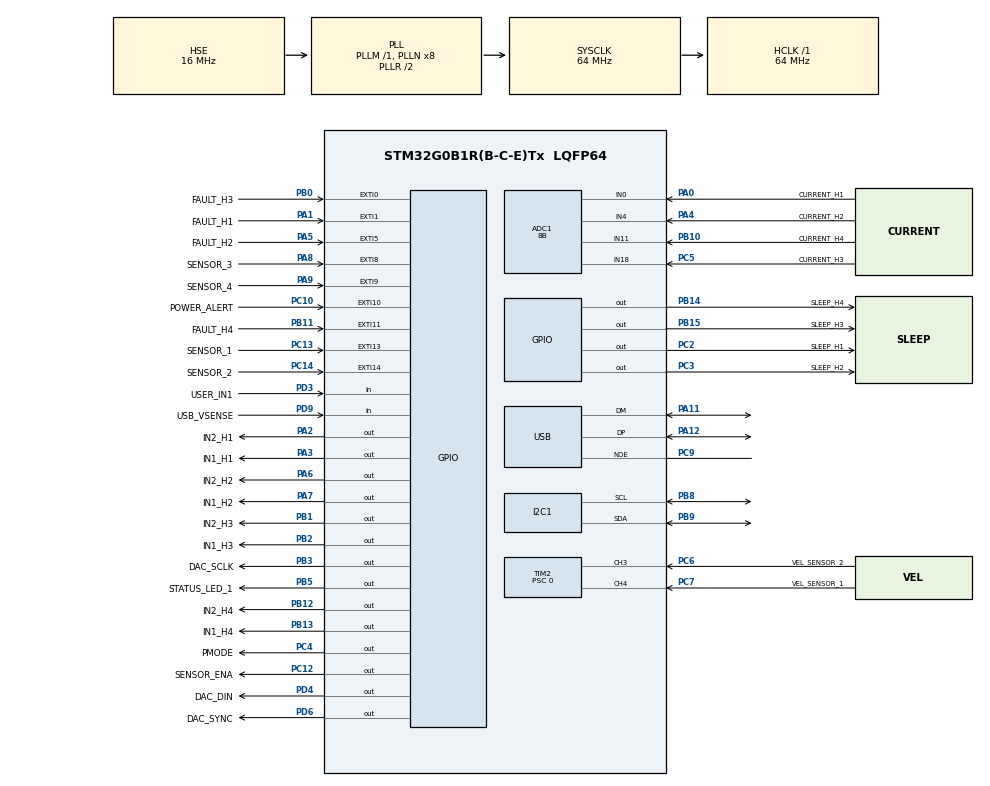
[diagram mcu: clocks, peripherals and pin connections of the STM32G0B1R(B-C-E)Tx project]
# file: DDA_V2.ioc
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ADC1.ContinuousConvMode=DISABLE
ADC1.DMAContinuousRequests=ENABLE
ADC1.EOCSelection=ADC_EOC_SEQ_CONV
ADC1.ExternalTrigConv=ADC_EXTERNALTRIG_T15_TRGO
ADC1.NbrOfConversion=1
ADC1.NbrOfConversionFlag=0
ADC1.Resolution=ADC_RESOLUTION_8B
ADC1.SamplingTimeCommon1=ADC_SAMPLETIME_79CYCLES_5
ADC1.SelectedChannel=ADC_CHANNEL_0|ADC_CHANNEL_4|ADC_CHANNEL_11|ADC_CHANNEL_18
ADC1.Sequencer=NOT_FULLY_CONFIGURABLE
ADC1.master=1
Dma.ADC1.0.Direction=DMA_PERIPH_TO_MEMORY
Dma.ADC1.0.EventEnable=DISABLE
Dma.ADC1.0.Instance=DMA1_Channel2
Dma.ADC1.0.MemDataAlignment=DMA_MDATAALIGN_BYTE
Dma.ADC1.0.MemInc=DMA_MINC_ENABLE
Dma.ADC1.0.Mode=DMA_NORMAL
Dma.ADC1.0.PeriphDataAlignment=DMA_PDATAALIGN_BYTE
Dma.ADC1.0.PeriphInc=DMA_PINC_DISABLE
Dma.ADC1.0.Polarity=HAL_DMAMUX_REQ_GEN_RISING
Dma.ADC1.0.Priority=DMA_PRIORITY_MEDIUM
Dma.ADC1.0.RequestNumber=1
Dma.ADC1.0.SignalID=NONE
Dma.ADC1.0.SyncEnable=DISABLE
Dma.ADC1.0.SyncPolarity=HAL_DMAMUX_SYNC_NO_EVENT
Dma.ADC1.0.SyncRequestNumber=1
Dma.ADC1.0.SyncSignalID=NONE
Dma.I2C1_RX.1.Direction=DMA_PERIPH_TO_MEMORY
Dma.I2C1_RX.1.EventEnable=DISABLE
Dma.I2C1_RX.1.Instance=DMA2_Channel1
Dma.I2C1_RX.1.MemDataAlignment=DMA_MDATAALIGN_BYTE
Dma.I2C1_RX.1.MemInc=DMA_MINC_ENABLE
Dma.I2C1_RX.1.Mode=DMA_NORMAL
Dma.I2C1_RX.1.PeriphDataAlignment=DMA_PDATAALIGN_BYTE
Dma.I2C1_RX.1.PeriphInc=DMA_PINC_DISABLE
Dma.I2C1_RX.1.Polarity=HAL_DMAMUX_REQ_GEN_RISING
Dma.I2C1_RX.1.Priority=DMA_PRIORITY_MEDIUM
Dma.I2C1_RX.1.RequestNumber=1
Dma.I2C1_RX.1.SignalID=NONE
Dma.I2C1_RX.1.SyncEnable=DISABLE
Dma.I2C1_RX.1.SyncPolarity=HAL_DMAMUX_SYNC_NO_EVENT
Dma.I2C1_RX.1.SyncRequestNumber=1
Dma.I2C1_RX.1.SyncSignalID=NONE
Dma.I2C1_TX.2.Direction=DMA_MEMORY_TO_PERIPH
Dma.I2C1_TX.2.EventEnable=DISABLE
Dma.I2C1_TX.2.Instance=DMA2_Channel2
Dma.I2C1_TX.2.MemDataAlignment=DMA_MDATAALIGN_BYTE
Dma.I2C1_TX.2.MemInc=DMA_MINC_ENABLE
Dma.I2C1_TX.2.Mode=DMA_NORMAL
Dma.I2C1_TX.2.PeriphDataAlignment=DMA_PDATAALIGN_BYTE
Dma.I2C1_TX.2.PeriphInc=DMA_PINC_DISABLE
Dma.I2C1_TX.2.Polarity=HAL_DMAMUX_REQ_GEN_RISING
Dma.I2C1_TX.2.Priority=DMA_PRIORITY_MEDIUM
Dma.I2C1_TX.2.RequestNumber=1
Dma.I2C1_TX.2.SignalID=NONE
Dma.I2C1_TX.2.SyncEnable=DISABLE
Dma.I2C1_TX.2.SyncPolarity=HAL_DMAMUX_SYNC_NO_EVENT
Dma.I2C1_TX.2.SyncRequestNumber=1
Dma.I2C1_TX.2.SyncSignalID=NONE
Dma.Request0=ADC1
Dma.Request1=I2C1_RX
Dma.Request2=I2C1_TX
I2C1.Timing=0x10B17DB5
Mcu.Family=STM32G0
Mcu.Name=STM32G0B1R(B-C-E)Tx
Mcu.Package=LQFP64
NVIC.DMA1_Ch4_7_DMA2_Ch1_5_DMAMUX1_OVR_IRQn=true\:0\:0\:false\:false\:true\:false\:true\:true
NVIC.DMA1_Channel2_3_IRQn=true\:0\:0\:false\:false\:true\:false\:true\:true
NVIC.I2C1_IRQn=true\:1\:0\:false\:false\:true\:true\:true\:true
NVIC.TIM3_TIM4_IRQn=true\:0\:0\:false\:false\:true\:true\:true\:true
NVIC.TIM7_LPTIM2_IRQn=true\:1\:0\:false\:false\:true\:true\:true\:true
NVIC.USB_UCPD1_2_IRQn=true\:1\:0\:false\:false\:true\:false\:true\:true
PA0.GPIO_Label=CURRENT_H1
PA0.Mode=IN0
PA0.Signal=ADC1_IN0
PA1.GPIO_Label=FAULT_H1
PA1.GPIO_ModeDefaultEXTI=GPIO_MODE_IT_FALLING
PA1.Signal=GPXTI1
PA11\ [PA9].Mode=Device
PA11\ [PA9].Signal=USB_DM
PA12\ [PA10].Mode=Device
PA12\ [PA10].Signal=USB_DP
PA13.Mode=Serial_Wire
PA13.Signal=SYS_SWDIO
PA14-BOOT0.Mode=Serial_Wire
PA14-BOOT0.Signal=SYS_SWCLK
PA2.GPIO_Label=IN2_H1
PA2.Signal=GPIO_Output
PA3.GPIO_Label=IN1_H1
PA3.Signal=GPIO_Output
PA4.GPIO_Label=CURRENT_H2
PA4.Mode=IN4
PA4.Signal=ADC1_IN4
PA5.GPIO_Label=FAULT_H2
PA5.GPIO_ModeDefaultEXTI=GPIO_MODE_IT_FALLING
PA5.Signal=GPXTI5
PA6.GPIO_Label=IN2_H2
PA6.Signal=GPIO_Output
PA7.GPIO_Label=IN1_H2
PA7.Signal=GPIO_Output
PA8.GPIO_Label=SENSOR_3
PA8.GPIO_ModeDefaultEXTI=GPIO_MODE_IT_RISING_FALLING
PA8.Signal=GPXTI8
PA9.GPIO_Label=SENSOR_4
PA9.GPIO_ModeDefaultEXTI=GPIO_MODE_IT_RISING_FALLING
PA9.Signal=GPXTI9
PB0.GPIO_Label=FAULT_H3
PB0.GPIO_ModeDefaultEXTI=GPIO_MODE_IT_FALLING
PB0.Signal=GPXTI0
PB1.GPIO_Label=IN2_H3
PB1.Signal=GPIO_Output
PB10.GPIO_Label=CURRENT_H4
PB10.Mode=IN11
PB10.Signal=ADC1_IN11
PB11.GPIO_Label=FAULT_H4
PB11.GPIO_ModeDefaultEXTI=GPIO_MODE_IT_FALLING
PB11.Signal=GPXTI11
PB12.GPIO_Label=IN2_H4
PB12.Signal=GPIO_Output
PB13.GPIO_Label=IN1_H4
PB13.Signal=GPIO_Output
PB14.GPIO_Label=SLEEP_H4
PB14.GPIO_PuPd=GPIO_PULLDOWN
PB14.Signal=GPIO_Output
PB15.GPIO_Label=SLEEP_H3
PB15.GPIO_PuPd=GPIO_PULLDOWN
PB15.Signal=GPIO_Output
PB2.GPIO_Label=IN1_H3
PB2.Signal=GPIO_Output
PB3.GPIO_Label=DAC_SCLK
PB3.PinState=GPIO_PIN_RESET
PB3.Signal=GPIO_Output
PB5.GPIO_Label=STATUS_LED_1
PB5.Signal=GPIO_Output
PB8.Mode=I2C
PB8.Signal=I2C1_SCL
PB9.Mode=I2C
PB9.Signal=I2C1_SDA
PC10.GPIO_Label=POWER_ALERT
PC10.GPIO_ModeDefaultEXTI=GPIO_MODE_IT_FALLING
PC10.Signal=GPXTI10
PC12.GPIO_Label=SENSOR_ENA
PC12.PinState=GPIO_PIN_SET
PC12.Signal=GPIO_Output
PC13.GPIO_Label=SENSOR_1
PC13.GPIO_ModeDefaultEXTI=GPIO_MODE_IT_RISING_FALLING
PC13.Signal=GPXTI13
PC14-OSC32_IN\ (PC14).GPIO_Label=SENSOR_2
PC14-OSC32_IN\ (PC14).GPIO_ModeDefaultEXTI=GPIO_MODE_IT_RISING_FALLING
PC14-OSC32_IN\ (PC14).Signal=GPXTI14
PC2.GPIO_Label=SLEEP_H1
PC2.GPIO_PuPd=GPIO_PULLDOWN
PC2.Signal=GPIO_Output
PC3.GPIO_Label=SLEEP_H2
PC3.GPIO_PuPd=GPIO_PULLDOWN
PC3.Signal=GPIO_Output
PC4.GPIO_Label=PMODE
PC4.PinState=GPIO_PIN_SET
PC4.Signal=GPIO_Output
PC5.GPIO_Label=CURRENT_H3
PC5.Mode=IN18
PC5.Signal=ADC1_IN18
PC6.GPIO_Label=VEL_SENSOR_2
PC6.Signal=S_TIM2_CH3
PC7.GPIO_Label=VEL_SENSOR_1
PC7.Signal=S_TIM2_CH4
PC9.GPIO_PuPd=GPIO_PULLDOWN
PC9.Mode=Activate_OE
PC9.Signal=USB_NOE
PD3.GPIO_Label=USER_IN1
PD3.GPIO_PuPd=GPIO_PULLDOWN
PD3.Signal=GPIO_Input
PD4.GPIO_Label=DAC_DIN
PD4.PinState=GPIO_PIN_RESET
PD4.Signal=GPIO_Output
PD6.GPIO_Label=DAC_SYNC
PD6.PinState=GPIO_PIN_SET
PD6.Signal=GPIO_Output
PD9.GPIO_Label=USB_VSENSE
PD9.Signal=GPIO_Input
PF0-OSC_IN\ (PF0).Mode=HSE-External-Oscillator
PF0-OSC_IN\ (PF0).Signal=RCC_OSC_IN
PF1-OSC_OUT\ (PF1).Mode=HSE-External-Oscillator
PF1-OSC_OUT\ (PF1).Signal=RCC_OSC_OUT
ProjectManager.HeapSize=0x200
ProjectManager.StackSize=0x400
ProjectManager.TargetToolchain=CMake
RCC.ADCFreq_Value=64000000
RCC.AHBFreq_Value=64000000
RCC.CortexFreq_Value=64000000
RCC.EXTERNAL_CLOCK_VALUE=48000
RCC.HCLKFreq_Value=64000000
RCC.HSE_VALUE=16000000
RCC.HSI48_VALUE=48000000
RCC.HSI_VALUE=16000000
RCC.LSE_VALUE=32768
RCC.PLLSourceVirtual=RCC_PLLSOURCE_HSE
RCC.SYSCLKFreq_VALUE=64000000
RCC.SYSCLKSource=RCC_SYSCLKSOURCE_PLLCLK
RCC.USBFreq_Value=48000000
RCC.VCOOutputFreq_Value=128000000
SH.S_TIM2_CH3.0=TIM2_CH3,Input_Capture3_from_TI3
SH.S_TIM2_CH4.0=TIM2_CH4,Input_Capture4_from_TI4
TIM15.TIM_MasterOutputTrigger=TIM_TRGO_UPDATE
TIM2.Channel-Input_Capture3_from_TI3=TIM_CHANNEL_3
TIM2.Channel-Input_Capture4_from_TI4=TIM_CHANNEL_4
TIM2.Channel-PWM\ Generation3\ CH3=TIM_CHANNEL_3
TIM2.Period=0xffffffff
TIM2.Prescaler=0
TIM3.Period=19
TIM3.Prescaler=63999
TIM4.Period=10-1
USB_DEVICE.CLASS_NAME_FS=CDC
USB_DEVICE.MANUFACTURER_STRING=carte_DDA
USB_DEVICE.PRODUCT_STRING_CDC_FS=carte_DDA
USB_DEVICE.VirtualMode=Cdc
USB_DEVICE.VirtualModeFS=Cdc_FS
USB_DRD_FS.battery_charging_enable=DISABLE
VP_SYS_VS_DBSignals.Mode=DisableDeadBatterySignals
VP_TIM15_VS_ClockSourceITR.Mode=TriggerSource_ITR0
VP_TIM15_VS_ControllerModeClock.Mode=Clock Mode
VP_TIM16_VS_ClockSourceINT.Mode=Enable_Timer
VP_TIM17_VS_ClockSourceINT.Mode=Enable_Timer
VP_TIM3_VS_ClockSourceINT.Mode=Internal
VP_TIM4_VS_ClockSourceINT.Mode=Internal
VP_TIM4_VS_ClockSourceITR.Mode=TriggerSource_ITR2
VP_TIM4_VS_ControllerModeTrigger.Mode=Trigger Mode
VP_TIM7_VS_ClockSourceINT.Mode=Enable_Timer
VP_TIM7_VS_OPM.Mode=OPM_bit
VP_USB_DEVICE_VS_USB_DEVICE_CDC_FS.Mode=CDC_FS
board=custom

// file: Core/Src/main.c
/* USER CODE BEGIN Header */
/**
 ******************************************************************************
 * @file           main.c
 * @brief          Hardware startup and foreground application dispatch.
 ******************************************************************************
 * @attention
 *
 * Copyright (c) 2026 STMicroelectronics.
 * All rights reserved.
 *
 * This software is licensed under terms that can be found in the LICENSE file
 * in the root directory of this software component.
 * If no LICENSE file comes with this software, it is provided AS-IS.
 *
 ******************************************************************************
 */
/* USER CODE END Header */
#include "main.h"
#include "usb_device.h"

/* USER CODE BEGIN Includes */
#include "App/BoardApplication.h"
/* USER CODE END Includes */

ADC_HandleTypeDef hadc1;
DMA_HandleTypeDef hdma_adc1;

I2C_HandleTypeDef hi2c1;
DMA_HandleTypeDef hdma_i2c1_rx;
DMA_HandleTypeDef hdma_i2c1_tx;

TIM_HandleTypeDef htim2;
TIM_HandleTypeDef htim3;
TIM_HandleTypeDef htim4;
TIM_HandleTypeDef htim7;
TIM_HandleTypeDef htim15;
TIM_HandleTypeDef htim16;
TIM_HandleTypeDef htim17;

void SystemClock_Config(void);
static void MX_GPIO_Init(void);
static void MX_DMA_Init(void);
static void MX_ADC1_Init(void);
static void MX_I2C1_Init(void);
static void MX_TIM2_Init(void);
static void MX_TIM3_Init(void);
static void MX_TIM16_Init(void);
static void MX_TIM15_Init(void);
static void MX_TIM17_Init(void);
static void MX_TIM4_Init(void);
static void MX_TIM7_Init(void);
/* USER CODE BEGIN PFP */
void DdaEmergency_DisablePowerOutputs(void);

/* USER CODE END PFP */

int main(void)
{

  /* MCU Configuration--------------------------------------------------------*/

  /* Reset of all peripherals, Initializes the Flash interface and the Systick. */
  HAL_Init();

  /* Configure the system clock */
  SystemClock_Config();

  /* Initialize all configured peripherals */
  MX_GPIO_Init();
  MX_DMA_Init();
  MX_ADC1_Init();
  MX_I2C1_Init();
  MX_TIM2_Init();
  MX_TIM3_Init();
  MX_USB_Device_Init();
  MX_TIM16_Init();
  MX_TIM15_Init();
  MX_TIM17_Init();
  MX_TIM4_Init();
  MX_TIM7_Init();
  /* USER CODE BEGIN 2 */
  // Construct and initialize the C++ application only after every HAL
  // peripheral handle and timer instance is ready, then start USB only after
  // its callback targets have been published.
  DdaApplication_Initialize();
  MX_USB_Device_Init();

  /* USER CODE END 2 */

  /* Infinite loop */
  while (1) {

    /* USER CODE BEGIN 3 */
    // Keep application protocol and safety state machines in foreground;
    // their callbacks only signal or enqueue time-critical events.
    DdaApplication_Process();
  }
  /* USER CODE END 3 */
}

void SystemClock_Config(void)
{
  RCC_OscInitTypeDef RCC_OscInitStruct = {0};
  RCC_ClkInitTypeDef RCC_ClkInitStruct = {0};

  /** Configure the main internal regulator output voltage
  */
  HAL_PWREx_ControlVoltageScaling(PWR_REGULATOR_VOLTAGE_SCALE1);

  /** Initializes the RCC Oscillators according to the specified parameters
  * in the RCC_OscInitTypeDef structure.
  */
  RCC_OscInitStruct.OscillatorType = RCC_OSCILLATORTYPE_HSE|RCC_OSCILLATORTYPE_HSI48;
  RCC_OscInitStruct.HSEState = RCC_HSE_ON;
  RCC_OscInitStruct.HSI48State = RCC_HSI48_ON;
  RCC_OscInitStruct.PLL.PLLState = RCC_PLL_ON;
  RCC_OscInitStruct.PLL.PLLSource = RCC_PLLSOURCE_HSE;
  RCC_OscInitStruct.PLL.PLLM = RCC_PLLM_DIV1;
  RCC_OscInitStruct.PLL.PLLN = 8;
  RCC_OscInitStruct.PLL.PLLP = RCC_PLLP_DIV2;
  RCC_OscInitStruct.PLL.PLLQ = RCC_PLLQ_DIV2;
  RCC_OscInitStruct.PLL.PLLR = RCC_PLLR_DIV2;
  if (HAL_RCC_OscConfig(&RCC_OscInitStruct) != HAL_OK)
  {
    Error_Handler();
  }

  /** Initializes the CPU, AHB and APB buses clocks
  */
  RCC_ClkInitStruct.ClockType = RCC_CLOCKTYPE_HCLK|RCC_CLOCKTYPE_SYSCLK
                              |RCC_CLOCKTYPE_PCLK1;
  RCC_ClkInitStruct.SYSCLKSource = RCC_SYSCLKSOURCE_PLLCLK;
  RCC_ClkInitStruct.AHBCLKDivider = RCC_SYSCLK_DIV1;
  RCC_ClkInitStruct.APB1CLKDivider = RCC_HCLK_DIV1;

  if (HAL_RCC_ClockConfig(&RCC_ClkInitStruct, FLASH_LATENCY_2) != HAL_OK)
  {
    Error_Handler();
  }
}

static void MX_ADC1_Init(void)
{

  ADC_ChannelConfTypeDef sConfig = {0};

  /* USER CODE BEGIN ADC1_Init 1 */
  // Channels 0, 4, 11, and 18 sample the four bridge-current monitors as
  // unsigned 8-bit codes. The 79.5-cycle hardware sample interval lets the
  // DRV8874 IPROPI outputs settle after a bridge is enabled.
  /* USER CODE END ADC1_Init 1 */

  /** Configure the global features of the ADC (Clock, Resolution, Data Alignment and number of conversion)
  */
  hadc1.Instance = ADC1;
  hadc1.Init.ClockPrescaler = ADC_CLOCK_SYNC_PCLK_DIV2;
  hadc1.Init.Resolution = ADC_RESOLUTION_8B;
  hadc1.Init.DataAlign = ADC_DATAALIGN_RIGHT;
  hadc1.Init.ScanConvMode = ADC_SCAN_SEQ_FIXED;
  hadc1.Init.EOCSelection = ADC_EOC_SEQ_CONV;
  hadc1.Init.LowPowerAutoWait = DISABLE;
  hadc1.Init.LowPowerAutoPowerOff = DISABLE;
  hadc1.Init.ContinuousConvMode = DISABLE;
  hadc1.Init.NbrOfConversion = 1;
  hadc1.Init.DiscontinuousConvMode = DISABLE;
  hadc1.Init.ExternalTrigConv = ADC_EXTERNALTRIG_T15_TRGO;
  hadc1.Init.ExternalTrigConvEdge = ADC_EXTERNALTRIGCONVEDGE_RISING;
  hadc1.Init.DMAContinuousRequests = ENABLE;
  hadc1.Init.Overrun = ADC_OVR_DATA_PRESERVED;
  hadc1.Init.SamplingTimeCommon1 = ADC_SAMPLETIME_79CYCLES_5;
  hadc1.Init.OversamplingMode = DISABLE;
  hadc1.Init.TriggerFrequencyMode = ADC_TRIGGER_FREQ_HIGH;
  if (HAL_ADC_Init(&hadc1) != HAL_OK)
  {
    Error_Handler();
  }

  /** Configure Regular Channel
  */
  sConfig.Channel = ADC_CHANNEL_0;
  sConfig.Rank = ADC_RANK_CHANNEL_NUMBER;
  if (HAL_ADC_ConfigChannel(&hadc1, &sConfig) != HAL_OK)
  {
    Error_Handler();
  }

  /** Configure Regular Channel
  */
  sConfig.Channel = ADC_CHANNEL_4;
  if (HAL_ADC_ConfigChannel(&hadc1, &sConfig) != HAL_OK)
  {
    Error_Handler();
  }

  /** Configure Regular Channel
  */
  sConfig.Channel = ADC_CHANNEL_11;
  if (HAL_ADC_ConfigChannel(&hadc1, &sConfig) != HAL_OK)
  {
    Error_Handler();
  }

  /** Configure Regular Channel
  */
  sConfig.Channel = ADC_CHANNEL_18;
  if (HAL_ADC_ConfigChannel(&hadc1, &sConfig) != HAL_OK)
  {
    Error_Handler();
  }

}

static void MX_I2C1_Init(void)
{

  /* USER CODE BEGIN I2C1_Init 1 */
  // This timing word targets standard-mode operation from the 64 MHz PCLK1;
  // the board must provide external pull-ups because internal pulls are off.
  /* USER CODE END I2C1_Init 1 */
  hi2c1.Instance = I2C1;
  hi2c1.Init.Timing = 0x10B17DB5;
  hi2c1.Init.OwnAddress1 = 0;
  hi2c1.Init.AddressingMode = I2C_ADDRESSINGMODE_7BIT;
  hi2c1.Init.DualAddressMode = I2C_DUALADDRESS_DISABLE;
  hi2c1.Init.OwnAddress2 = 0;
  hi2c1.Init.OwnAddress2Masks = I2C_OA2_NOMASK;
  hi2c1.Init.GeneralCallMode = I2C_GENERALCALL_DISABLE;
  hi2c1.Init.NoStretchMode = I2C_NOSTRETCH_DISABLE;
  if (HAL_I2C_Init(&hi2c1) != HAL_OK)
  {
    Error_Handler();
  }

  /** Configure Analogue filter
  */
  if (HAL_I2CEx_ConfigAnalogFilter(&hi2c1, I2C_ANALOGFILTER_ENABLE) != HAL_OK)
  {
    Error_Handler();
  }

  /** Configure Digital filter
  */
  if (HAL_I2CEx_ConfigDigitalFilter(&hi2c1, 0) != HAL_OK)
  {
    Error_Handler();
  }

}

static void MX_TIM2_Init(void)
{

  TIM_MasterConfigTypeDef sMasterConfig = {0};
  TIM_IC_InitTypeDef sConfigIC = {0};

  /* USER CODE BEGIN TIM2_Init 1 */
  // A divide-by-64 prescaler produces a 1 MHz (1 us) free-running capture
  // counter from the 64 MHz timer clock. Channels 3 and 4 are configured for
  // rising-edge capture, but the application currently starts only the base.
  /* USER CODE END TIM2_Init 1 */
  htim2.Instance = TIM2;
  htim2.Init.Prescaler = 0;
  htim2.Init.CounterMode = TIM_COUNTERMODE_UP;
  htim2.Init.Period = 0xffffffff;
  htim2.Init.ClockDivision = TIM_CLOCKDIVISION_DIV1;
  htim2.Init.AutoReloadPreload = TIM_AUTORELOAD_PRELOAD_DISABLE;
  if (HAL_TIM_IC_Init(&htim2) != HAL_OK)
  {
    Error_Handler();
  }
  sMasterConfig.MasterOutputTrigger = TIM_TRGO_RESET;
  sMasterConfig.MasterSlaveMode = TIM_MASTERSLAVEMODE_DISABLE;
  if (HAL_TIMEx_MasterConfigSynchronization(&htim2, &sMasterConfig) != HAL_OK)
  {
    Error_Handler();
  }
  sConfigIC.ICPolarity = TIM_INPUTCHANNELPOLARITY_RISING;
  sConfigIC.ICSelection = TIM_ICSELECTION_DIRECTTI;
  sConfigIC.ICPrescaler = TIM_ICPSC_DIV1;
  sConfigIC.ICFilter = 0;
  if (HAL_TIM_IC_ConfigChannel(&htim2, &sConfigIC, TIM_CHANNEL_3) != HAL_OK)
  {
    Error_Handler();
  }
  if (HAL_TIM_IC_ConfigChannel(&htim2, &sConfigIC, TIM_CHANNEL_4) != HAL_OK)
  {
    Error_Handler();
  }

}

static void MX_TIM3_Init(void)
{

  TIM_ClockConfigTypeDef sClockSourceConfig = {0};
  TIM_MasterConfigTypeDef sMasterConfig = {0};

  htim3.Instance = TIM3;
  htim3.Init.Prescaler = 63999;
  htim3.Init.CounterMode = TIM_COUNTERMODE_UP;
  htim3.Init.Period = 19;
  htim3.Init.ClockDivision = TIM_CLOCKDIVISION_DIV1;
  htim3.Init.AutoReloadPreload = TIM_AUTORELOAD_PRELOAD_DISABLE;
  if (HAL_TIM_Base_Init(&htim3) != HAL_OK)
  {
    Error_Handler();
  }
  sClockSourceConfig.ClockSource = TIM_CLOCKSOURCE_INTERNAL;
  if (HAL_TIM_ConfigClockSource(&htim3, &sClockSourceConfig) != HAL_OK)
  {
    Error_Handler();
  }
  sMasterConfig.MasterOutputTrigger = TIM_TRGO_RESET;
  sMasterConfig.MasterSlaveMode = TIM_MASTERSLAVEMODE_DISABLE;
  if (HAL_TIMEx_MasterConfigSynchronization(&htim3, &sMasterConfig) != HAL_OK)
  {
    Error_Handler();
  }

}

static void MX_TIM4_Init(void)
{

  TIM_ClockConfigTypeDef sClockSourceConfig = {0};
  TIM_SlaveConfigTypeDef sSlaveConfig = {0};
  TIM_MasterConfigTypeDef sMasterConfig = {0};

  htim4.Instance = TIM4;
  htim4.Init.Prescaler = 0;
  htim4.Init.CounterMode = TIM_COUNTERMODE_UP;
  htim4.Init.Period = 10-1;
  htim4.Init.ClockDivision = TIM_CLOCKDIVISION_DIV1;
  htim4.Init.AutoReloadPreload = TIM_AUTORELOAD_PRELOAD_DISABLE;
  if (HAL_TIM_Base_Init(&htim4) != HAL_OK)
  {
    Error_Handler();
  }
  sClockSourceConfig.ClockSource = TIM_CLOCKSOURCE_INTERNAL;
  if (HAL_TIM_ConfigClockSource(&htim4, &sClockSourceConfig) != HAL_OK)
  {
    Error_Handler();
  }
  sSlaveConfig.SlaveMode = TIM_SLAVEMODE_TRIGGER;
  sSlaveConfig.InputTrigger = TIM_TS_ITR2;
  if (HAL_TIM_SlaveConfigSynchro(&htim4, &sSlaveConfig) != HAL_OK)
  {
    Error_Handler();
  }
  sMasterConfig.MasterOutputTrigger = TIM_TRGO_RESET;
  sMasterConfig.MasterSlaveMode = TIM_MASTERSLAVEMODE_DISABLE;
  if (HAL_TIMEx_MasterConfigSynchronization(&htim4, &sMasterConfig) != HAL_OK)
  {
    Error_Handler();
  }

}

static void MX_TIM7_Init(void)
{

  TIM_MasterConfigTypeDef sMasterConfig = {0};

  htim7.Instance = TIM7;
  htim7.Init.Prescaler = 0;
  htim7.Init.CounterMode = TIM_COUNTERMODE_UP;
  htim7.Init.Period = 65535;
  htim7.Init.AutoReloadPreload = TIM_AUTORELOAD_PRELOAD_DISABLE;
  if (HAL_TIM_Base_Init(&htim7) != HAL_OK)
  {
    Error_Handler();
  }
  if (HAL_TIM_OnePulse_Init(&htim7, TIM_OPMODE_SINGLE) != HAL_OK)
  {
    Error_Handler();
  }
  sMasterConfig.MasterOutputTrigger = TIM_TRGO_RESET;
  sMasterConfig.MasterSlaveMode = TIM_MASTERSLAVEMODE_DISABLE;
  if (HAL_TIMEx_MasterConfigSynchronization(&htim7, &sMasterConfig) != HAL_OK)
  {
    Error_Handler();
  }

}

static void MX_TIM15_Init(void)
{

  TIM_SlaveConfigTypeDef sSlaveConfig = {0};
  TIM_MasterConfigTypeDef sMasterConfig = {0};

  htim15.Instance = TIM15;
  htim15.Init.Prescaler = 0;
  htim15.Init.CounterMode = TIM_COUNTERMODE_UP;
  htim15.Init.Period = 65535;
  htim15.Init.ClockDivision = TIM_CLOCKDIVISION_DIV1;
  htim15.Init.RepetitionCounter = 0;
  htim15.Init.AutoReloadPreload = TIM_AUTORELOAD_PRELOAD_DISABLE;
  if (HAL_TIM_Base_Init(&htim15) != HAL_OK)
  {
    Error_Handler();
  }
  sSlaveConfig.SlaveMode = TIM_SLAVEMODE_EXTERNAL1;
  sSlaveConfig.InputTrigger = TIM_TS_ITR0;
  if (HAL_TIM_SlaveConfigSynchro(&htim15, &sSlaveConfig) != HAL_OK)
  {
    Error_Handler();
  }
  sMasterConfig.MasterOutputTrigger = TIM_TRGO_UPDATE;
  sMasterConfig.MasterSlaveMode = TIM_MASTERSLAVEMODE_DISABLE;
  if (HAL_TIMEx_MasterConfigSynchronization(&htim15, &sMasterConfig) != HAL_OK)
  {
    Error_Handler();
  }

}

static void MX_TIM16_Init(void)
{

  htim16.Instance = TIM16;
  htim16.Init.Prescaler = 0;
  htim16.Init.CounterMode = TIM_COUNTERMODE_UP;
  htim16.Init.Period = 65535;
  htim16.Init.ClockDivision = TIM_CLOCKDIVISION_DIV1;
  htim16.Init.RepetitionCounter = 0;
  htim16.Init.AutoReloadPreload = TIM_AUTORELOAD_PRELOAD_DISABLE;
  if (HAL_TIM_Base_Init(&htim16) != HAL_OK)
  {
    Error_Handler();
  }

}

static void MX_TIM17_Init(void)
{

  htim17.Instance = TIM17;
  htim17.Init.Prescaler = 0;
  htim17.Init.CounterMode = TIM_COUNTERMODE_UP;
  htim17.Init.Period = 65535;
  htim17.Init.ClockDivision = TIM_CLOCKDIVISION_DIV1;
  htim17.Init.RepetitionCounter = 0;
  htim17.Init.AutoReloadPreload = TIM_AUTORELOAD_PRELOAD_DISABLE;
  if (HAL_TIM_Base_Init(&htim17) != HAL_OK)
  {
    Error_Handler();
  }

}

static void MX_DMA_Init(void)
{

  /* DMA controller clock enable */
  __HAL_RCC_DMA1_CLK_ENABLE();
  __HAL_RCC_DMA2_CLK_ENABLE();

  /* DMA interrupt init */
  /* DMA1_Channel2_3_IRQn interrupt configuration */
  HAL_NVIC_SetPriority(DMA1_Channel2_3_IRQn, 0, 0);
  HAL_NVIC_EnableIRQ(DMA1_Channel2_3_IRQn);
  /* DMA1_Ch4_7_DMA2_Ch1_5_DMAMUX1_OVR_IRQn interrupt configuration */
  HAL_NVIC_SetPriority(DMA1_Ch4_7_DMA2_Ch1_5_DMAMUX1_OVR_IRQn, 0, 0);
  HAL_NVIC_EnableIRQ(DMA1_Ch4_7_DMA2_Ch1_5_DMAMUX1_OVR_IRQn);

}

static void MX_GPIO_Init(void)
{
  GPIO_InitTypeDef GPIO_InitStruct = {0};
  /* USER CODE BEGIN MX_GPIO_Init_1 */
  // Output data registers are loaded with safe levels before pins switch to
  // output mode: every H-bridge control and sensor enable stays low, while
  // PMODE and DAC_SYNC stay high.
  /* USER CODE END MX_GPIO_Init_1 */

  /* GPIO Ports Clock Enable */
  __HAL_RCC_GPIOC_CLK_ENABLE();
  __HAL_RCC_GPIOF_CLK_ENABLE();
  __HAL_RCC_GPIOA_CLK_ENABLE();
  __HAL_RCC_GPIOB_CLK_ENABLE();
  __HAL_RCC_GPIOD_CLK_ENABLE();

  /*Configure GPIO pin Output Level */
  HAL_GPIO_WritePin(GPIOC, SENSOR_ENA_Pin|PMODE_Pin, GPIO_PIN_SET);

  /*Configure GPIO pin Output Level */
  HAL_GPIO_WritePin(GPIOC, SLEEP_H1_Pin|SLEEP_H2_Pin, GPIO_PIN_RESET);

  /*Configure GPIO pin Output Level */
  HAL_GPIO_WritePin(GPIOA, IN2_H1_Pin|IN1_H1_Pin|IN2_H2_Pin|IN1_H2_Pin, GPIO_PIN_RESET);

  /*Configure GPIO pin Output Level */
  HAL_GPIO_WritePin(GPIOB, IN2_H3_Pin|IN1_H3_Pin|IN2_H4_Pin|IN1_H4_Pin
                          |SLEEP_H4_Pin|SLEEP_H3_Pin|DAC_SCLK_Pin|STATUS_LED_1_Pin, GPIO_PIN_RESET);

  /*Configure GPIO pin Output Level */
  HAL_GPIO_WritePin(DAC_DIN_GPIO_Port, DAC_DIN_Pin, GPIO_PIN_RESET);

  /*Configure GPIO pin Output Level */
  HAL_GPIO_WritePin(DAC_SYNC_GPIO_Port, DAC_SYNC_Pin, GPIO_PIN_SET);

  /*Configure GPIO pins : SENSOR_ENA_Pin PMODE_Pin */
  GPIO_InitStruct.Pin = SENSOR_ENA_Pin|PMODE_Pin;
  GPIO_InitStruct.Mode = GPIO_MODE_OUTPUT_PP;
  GPIO_InitStruct.Pull = GPIO_NOPULL;
  GPIO_InitStruct.Speed = GPIO_SPEED_FREQ_LOW;
  HAL_GPIO_Init(GPIOC, &GPIO_InitStruct);

  /*Configure GPIO pins : SENSOR_1_Pin SENSOR_2_Pin */
  GPIO_InitStruct.Pin = SENSOR_1_Pin|SENSOR_2_Pin;
  GPIO_InitStruct.Mode = GPIO_MODE_IT_RISING_FALLING;
  GPIO_InitStruct.Pull = GPIO_NOPULL;
  HAL_GPIO_Init(GPIOC, &GPIO_InitStruct);

  /*Configure GPIO pins : SLEEP_H1_Pin SLEEP_H2_Pin */
  GPIO_InitStruct.Pin = SLEEP_H1_Pin|SLEEP_H2_Pin;
  GPIO_InitStruct.Mode = GPIO_MODE_OUTPUT_PP;
  GPIO_InitStruct.Pull = GPIO_PULLDOWN;
  GPIO_InitStruct.Speed = GPIO_SPEED_FREQ_LOW;
  HAL_GPIO_Init(GPIOC, &GPIO_InitStruct);

  /*Configure GPIO pins : FAULT_H1_Pin FAULT_H2_Pin */
  GPIO_InitStruct.Pin = FAULT_H1_Pin|FAULT_H2_Pin;
  GPIO_InitStruct.Mode = GPIO_MODE_IT_FALLING;
  GPIO_InitStruct.Pull = GPIO_NOPULL;
  HAL_GPIO_Init(GPIOA, &GPIO_InitStruct);

  /*Configure GPIO pins : IN2_H1_Pin IN1_H1_Pin IN2_H2_Pin IN1_H2_Pin */
  GPIO_InitStruct.Pin = IN2_H1_Pin|IN1_H1_Pin|IN2_H2_Pin|IN1_H2_Pin;
  GPIO_InitStruct.Mode = GPIO_MODE_OUTPUT_PP;
  GPIO_InitStruct.Pull = GPIO_NOPULL;
  GPIO_InitStruct.Speed = GPIO_SPEED_FREQ_LOW;
  HAL_GPIO_Init(GPIOA, &GPIO_InitStruct);

  /*Configure GPIO pins : FAULT_H3_Pin FAULT_H4_Pin */
  GPIO_InitStruct.Pin = FAULT_H3_Pin|FAULT_H4_Pin;
  GPIO_InitStruct.Mode = GPIO_MODE_IT_FALLING;
  GPIO_InitStruct.Pull = GPIO_NOPULL;
  HAL_GPIO_Init(GPIOB, &GPIO_InitStruct);

  /*Configure GPIO pins : IN2_H3_Pin IN1_H3_Pin IN2_H4_Pin IN1_H4_Pin
                           DAC_SCLK_Pin STATUS_LED_1_Pin */
  GPIO_InitStruct.Pin = IN2_H3_Pin|IN1_H3_Pin|IN2_H4_Pin|IN1_H4_Pin
                          |DAC_SCLK_Pin|STATUS_LED_1_Pin;
  GPIO_InitStruct.Mode = GPIO_MODE_OUTPUT_PP;
  GPIO_InitStruct.Pull = GPIO_NOPULL;
  GPIO_InitStruct.Speed = GPIO_SPEED_FREQ_LOW;
  HAL_GPIO_Init(GPIOB, &GPIO_InitStruct);

  /*Configure GPIO pins : SLEEP_H4_Pin SLEEP_H3_Pin */
  GPIO_InitStruct.Pin = SLEEP_H4_Pin|SLEEP_H3_Pin;
  GPIO_InitStruct.Mode = GPIO_MODE_OUTPUT_PP;
  GPIO_InitStruct.Pull = GPIO_PULLDOWN;
  GPIO_InitStruct.Speed = GPIO_SPEED_FREQ_LOW;
  HAL_GPIO_Init(GPIOB, &GPIO_InitStruct);

  /*Configure GPIO pins : SENSOR_3_Pin SENSOR_4_Pin */
  GPIO_InitStruct.Pin = SENSOR_3_Pin|SENSOR_4_Pin;
  GPIO_InitStruct.Mode = GPIO_MODE_IT_RISING_FALLING;
  GPIO_InitStruct.Pull = GPIO_NOPULL;
  HAL_GPIO_Init(GPIOA, &GPIO_InitStruct);

  /*Configure GPIO pin : USB_VSENSE_Pin */
  GPIO_InitStruct.Pin = USB_VSENSE_Pin;
  GPIO_InitStruct.Mode = GPIO_MODE_INPUT;
  GPIO_InitStruct.Pull = GPIO_NOPULL;
  HAL_GPIO_Init(USB_VSENSE_GPIO_Port, &GPIO_InitStruct);

  /*Configure GPIO pin : USER_IN1_Pin */
  GPIO_InitStruct.Pin = USER_IN1_Pin;
  GPIO_InitStruct.Mode = GPIO_MODE_INPUT;
  GPIO_InitStruct.Pull = GPIO_PULLDOWN;
  HAL_GPIO_Init(USER_IN1_GPIO_Port, &GPIO_InitStruct);

  /*Configure GPIO pins : DAC_DIN_Pin DAC_SYNC_Pin */
  GPIO_InitStruct.Pin = DAC_DIN_Pin|DAC_SYNC_Pin;
  GPIO_InitStruct.Mode = GPIO_MODE_OUTPUT_PP;
  GPIO_InitStruct.Pull = GPIO_NOPULL;
  GPIO_InitStruct.Speed = GPIO_SPEED_FREQ_LOW;
  HAL_GPIO_Init(GPIOD, &GPIO_InitStruct);

  /*Configure GPIO pin : POWER_ALERT_Pin */
  GPIO_InitStruct.Pin = POWER_ALERT_Pin;
  GPIO_InitStruct.Mode = GPIO_MODE_IT_FALLING;
  GPIO_InitStruct.Pull = GPIO_NOPULL;
  HAL_GPIO_Init(POWER_ALERT_GPIO_Port, &GPIO_InitStruct);

  /* USER CODE BEGIN MX_GPIO_Init_2 */

  // EXTI stays disabled until the C++ application has
  // published its callback targets, sampled all fault pins, and established
  // safe state.

  /* USER CODE END MX_GPIO_Init_2 */
}

void Error_Handler(void)
{
  /* USER CODE BEGIN Error_Handler_Debug */
  DdaEmergency_DisablePowerOutputs();
  __disable_irq();
#if defined(DDA_RELEASE_BUILD)
  NVIC_SystemReset();
#endif
  while (1) {
  }
  /* USER CODE END Error_Handler_Debug */
}
#ifdef USE_FULL_ASSERT
/**
  * @brief  Reports the name of the source file and the source line number
  *         where the assert_param error has occurred.
  * @param  file: pointer to the source file name
  * @param  line: assert_param error line source number
  * @retval None
  */
void assert_failed(uint8_t *file, uint32_t line)
{
  /* USER CODE BEGIN 6 */
  /* User can add his own implementation to report the file name and line
     number, ex: printf("Wrong parameters value: file %s on line %d\r\n", file,
     line) */
  /* USER CODE END 6 */
}
#endif /* USE_FULL_ASSERT */
